VERSION ""

NS_ :

BS_:

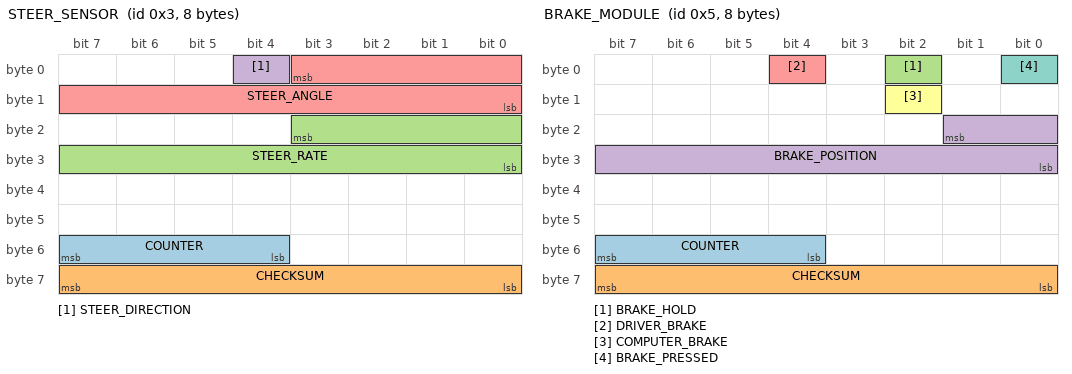
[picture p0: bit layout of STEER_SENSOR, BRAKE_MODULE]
BO_ 3 STEER_SENSOR: 8 XXX
 SG_ COUNTER : 55|4@0+ (1,0) [0|15] "" XXX
 SG_ CHECKSUM : 63|8@0+ (1,0) [0|255] "" XXX
 SG_ STEER_RATE : 19|12@0- (0.5,0) [0|255] "" XXX
 SG_ STEER_DIRECTION : 4|1@0+ (1,2) [0|1] "" XXX
 SG_ STEER_ANGLE : 3|12@0- (-0.5,0) [-500|500] "degrees" XXX

BO_ 5 BRAKE_MODULE: 8 XXX
 SG_ COUNTER : 55|4@0+ (1,0) [0|15] "" XXX
 SG_ CHECKSUM : 63|8@0+ (1,0) [0|255] "" XXX
 SG_ BRAKE_HOLD : 2|1@0+ (1,0) [0|1] "" XXX
 SG_ BRAKE_POSITION : 17|10@0+ (1,0) [0|65535] "" XXX
 SG_ DRIVER_BRAKE : 4|1@0+ (1,0) [0|1] "" XXX
 SG_ COMPUTER_BRAKE : 10|1@0+ (1,0) [0|1] "" XXX
 SG_ BRAKE_PRESSED : 0|1@1+ (1,0) [0|1] "" XXX

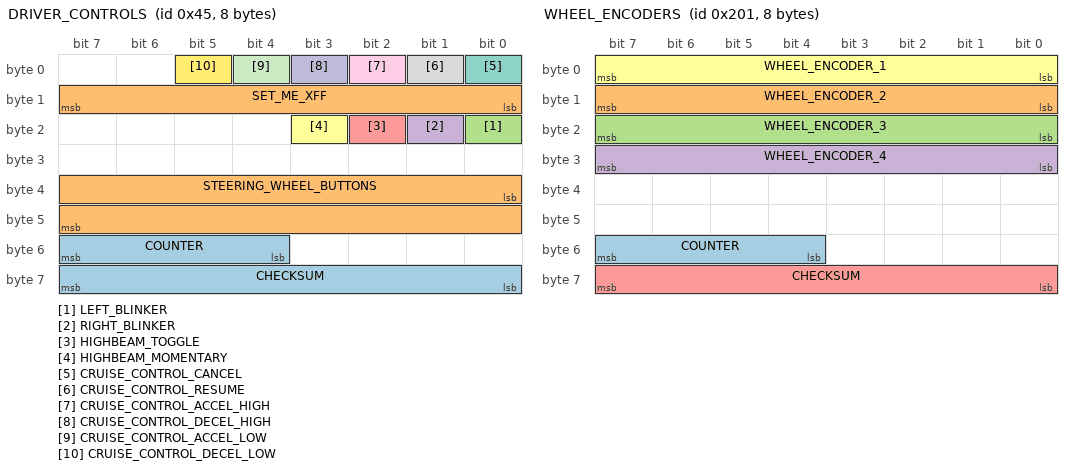
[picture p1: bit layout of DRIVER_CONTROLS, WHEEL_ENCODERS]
BO_ 69 DRIVER_CONTROLS: 8 XXX
 SG_ COUNTER : 55|4@0+ (1,0) [0|15] "" XXX
 SG_ STEERING_WHEEL_BUTTONS : 32|16@1+ (1,0) [0|255] "4 directional, 2 volume control & 2 phone buttons" XXX
 SG_ LEFT_BLINKER : 16|1@0+ (1,0) [0|1] "" XXX
 SG_ RIGHT_BLINKER : 17|1@0+ (1,0) [0|1] "" XXX
 SG_ HIGHBEAM_TOGGLE : 18|1@0+ (1,0) [0|1] "" XXX
 SG_ HIGHBEAM_MOMENTARY : 19|1@0+ (1,0) [0|1] "" XXX
 SG_ CRUISE_CONTROL_CANCEL : 0|1@0+ (1,0) [0|1] "" XXX
 SG_ CRUISE_CONTROL_RESUME : 1|1@0+ (1,0) [0|1] "" XXX
 SG_ CRUISE_CONTROL_ACCEL_HIGH : 2|1@0+ (1,0) [0|1] "" XXX
 SG_ CRUISE_CONTROL_DECEL_HIGH : 3|1@0+ (1,0) [0|1] "" XXX
 SG_ CRUISE_CONTROL_ACCEL_LOW : 4|1@0+ (1,0) [0|1] "" XXX
 SG_ CRUISE_CONTROL_DECEL_LOW : 5|1@0+ (1,0) [0|1] "" XXX
 SG_ CHECKSUM : 63|8@0+ (1,0) [0|255] "" XXX
 SG_ SET_ME_XFF : 15|8@0+ (1,0) [0|255] "" XXX

BO_ 513 WHEEL_ENCODERS: 8 XXX
 SG_ COUNTER : 55|4@0+ (1,0) [0|15] "" XXX
 SG_ WHEEL_ENCODER_2 : 15|8@0+ (1,0) [0|255] "" XXX
 SG_ WHEEL_ENCODER_3 : 23|8@0+ (1,0) [0|255] "" XXX
 SG_ WHEEL_ENCODER_4 : 31|8@0+ (1,0) [0|255] "" XXX
 SG_ CHECKSUM : 56|8@1+ (1,0) [0|255] "" XXX
 SG_ WHEEL_ENCODER_1 : 7|8@0+ (1,0) [0|255] "" XXX

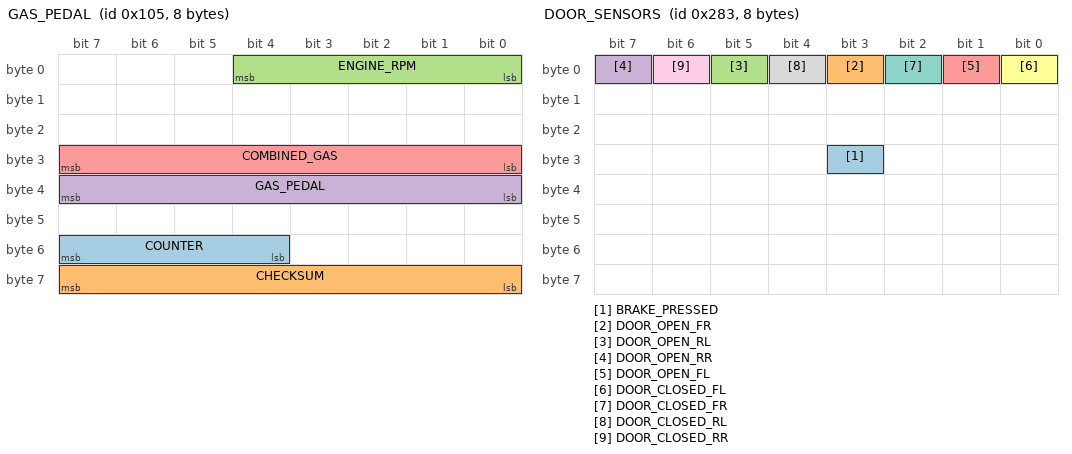
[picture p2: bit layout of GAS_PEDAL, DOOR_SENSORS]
BO_ 261 GAS_PEDAL: 8 XXX
 SG_ COUNTER : 55|4@0+ (1,0) [0|15] "" XXX
 SG_ CHECKSUM : 63|8@0+ (1,0) [0|255] "" XXX
 SG_ ENGINE_RPM : 4|5@0+ (1,0) [0|255] "" XXX
 SG_ GAS_PEDAL : 39|8@0+ (1,0) [0|255] "" XXX
 SG_ COMBINED_GAS : 31|8@0+ (1,0) [0|255] "" XXX

BO_ 643 DOOR_SENSORS: 8 XXX
 SG_ BRAKE_PRESSED : 27|1@0+ (1,0) [0|1] "" XXX
 SG_ DOOR_OPEN_FR : 3|1@1+ (1,0) [0|3] "" XXX
 SG_ DOOR_OPEN_RL : 5|1@0+ (1,0) [0|3] "" XXX
 SG_ DOOR_OPEN_RR : 7|1@0+ (1,0) [0|3] "" XXX
 SG_ DOOR_OPEN_FL : 1|1@0+ (1,0) [0|1] "" XXX
 SG_ DOOR_CLOSED_FL : 0|1@0+ (1,0) [0|1] "" XXX
 SG_ DOOR_CLOSED_FR : 2|1@0+ (1,0) [0|1] "" XXX
 SG_ DOOR_CLOSED_RL : 4|1@0+ (1,0) [0|1] "" XXX
 SG_ DOOR_CLOSED_RR : 6|1@0+ (1,0) [0|1] "" XXX

BO_ 885 SEATBELT_SENSORS: 8 XXX
 SG_ SEATBELT_DRIVER_LATCHED : 16|1@0+ (1,0) [0|1] "" XXX
 SG_ SEATBELT_PASSENGER_LATCHED : 18|1@0+ (1,0) [0|1] "" XXX

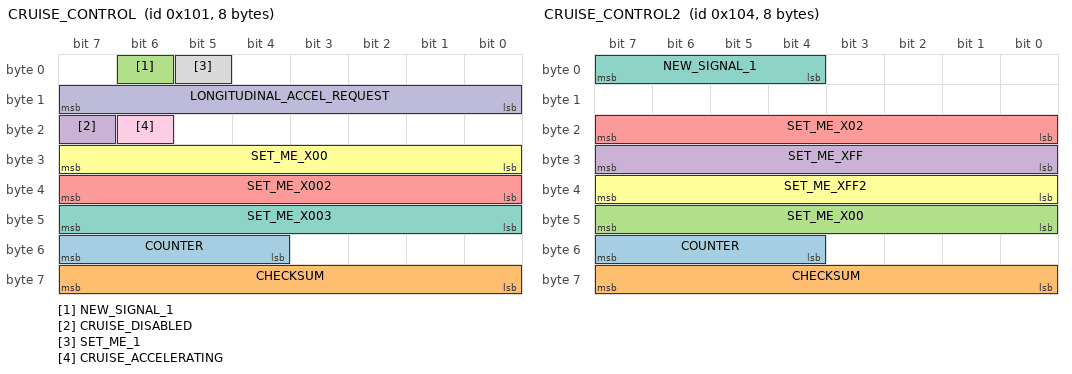
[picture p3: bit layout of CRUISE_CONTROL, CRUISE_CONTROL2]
BO_ 257 CRUISE_CONTROL: 8 XXX
 SG_ COUNTER : 55|4@0+ (1,0) [0|15] "" XXX
 SG_ CHECKSUM : 63|8@0+ (1,0) [0|255] "" XXX
 SG_ NEW_SIGNAL_1 : 6|1@0+ (1,0) [0|255] "" XXX
 SG_ CRUISE_DISABLED : 23|1@0+ (1,0) [0|1] "" XXX
 SG_ SET_ME_X002 : 39|8@0+ (1,0) [0|255] "" XXX
 SG_ SET_ME_X00 : 31|8@0+ (1,0) [0|255] "" XXX
 SG_ SET_ME_X003 : 47|8@0+ (1,0) [0|255] "" XXX
 SG_ SET_ME_1 : 5|1@0+ (1,0) [0|1] "" XXX
 SG_ CRUISE_ACCELERATING : 22|1@0+ (1,0) [0|1] "" XXX
 SG_ LONGITUDINAL_ACCEL_REQUEST : 15|8@0- (1,0) [0|127] "" XXX

BO_ 260 CRUISE_CONTROL2: 8 XXX
 SG_ COUNTER : 55|4@0+ (1,0) [0|15] "" XXX
 SG_ CHECKSUM : 63|8@0+ (1,0) [0|255] "" XXX
 SG_ SET_ME_X00 : 47|8@0+ (1,0) [0|255] "" XXX
 SG_ SET_ME_XFF : 31|8@0+ (1,0) [0|65535] "" XXX
 SG_ SET_ME_X02 : 23|8@0+ (1,0) [0|255] "" XXX
 SG_ SET_ME_XFF2 : 39|8@0+ (1,0) [0|255] "" XXX
 SG_ NEW_SIGNAL_1 : 7|4@0+ (1,0) [0|255] "" XXX

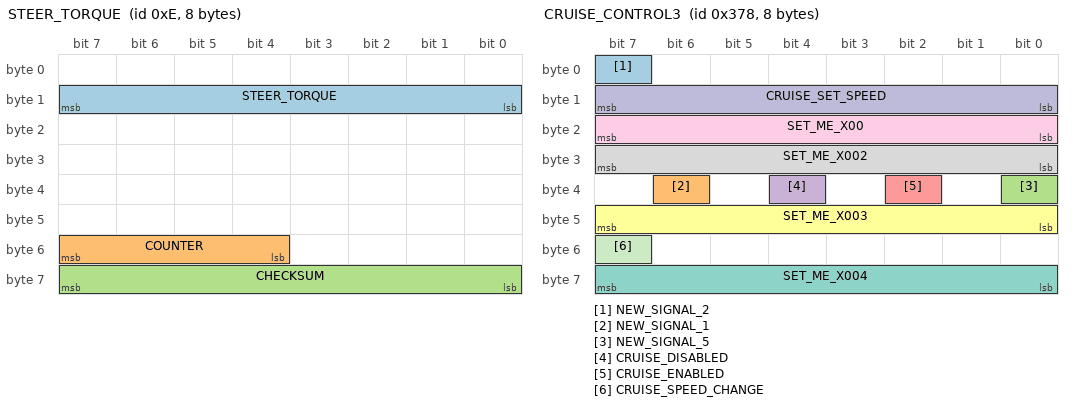
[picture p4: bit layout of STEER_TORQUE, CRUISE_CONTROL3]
BO_ 14 STEER_TORQUE: 8 XXX
 SG_ STEER_TORQUE : 15|8@0+ (1,0) [0|255] "" XXX
 SG_ COUNTER : 55|4@0+ (1,0) [0|15] "" XXX
 SG_ CHECKSUM : 63|8@0+ (1,0) [0|255] "" XXX

BO_ 888 CRUISE_CONTROL3: 8 XXX
 SG_ NEW_SIGNAL_2 : 7|1@0+ (1,0) [0|1] "" XXX
 SG_ NEW_SIGNAL_1 : 38|1@0+ (1,0) [0|1] "" XXX
 SG_ NEW_SIGNAL_5 : 32|1@0+ (1,0) [0|1] "" XXX
 SG_ CRUISE_DISABLED : 36|1@0+ (1,0) [0|1] "" XXX
 SG_ CRUISE_ENABLED : 34|1@0+ (1,0) [0|1] "" XXX
 SG_ SET_ME_X003 : 47|8@0+ (1,0) [0|255] "" XXX
 SG_ SET_ME_X004 : 63|8@0+ (1,0) [0|255] "" XXX
 SG_ SET_ME_X002 : 31|8@0+ (1,0) [0|255] "" XXX
 SG_ SET_ME_X00 : 23|8@0+ (1,0) [0|255] "" XXX
 SG_ CRUISE_SET_SPEED : 15|8@0+ (1,0) [0|63] "mph" XXX
 SG_ CRUISE_SPEED_CHANGE : 55|1@0+ (1,0) [0|1] "" XXX

BO_ 307 POWER_SEATS: 8 XXX
 SG_ DRIVER_FORWARD : 0|1@0+ (1,0) [0|1] "" XXX
 SG_ DRIVER_BACK : 1|1@0+ (1,0) [0|1] "" XXX

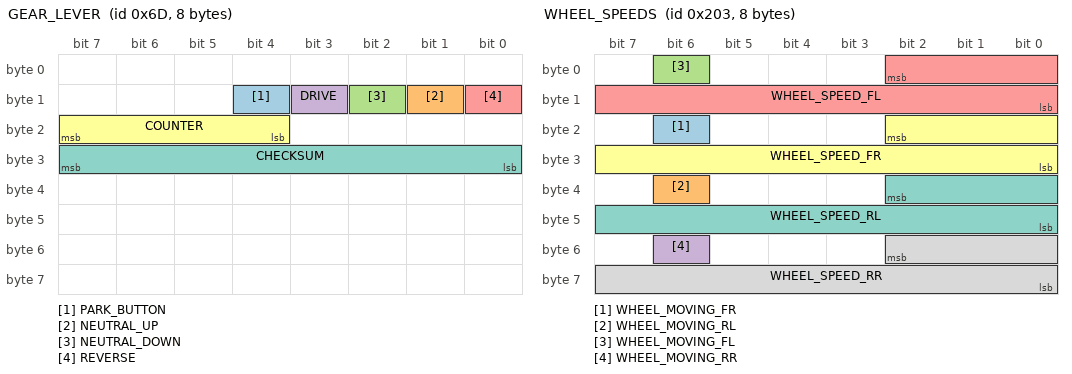
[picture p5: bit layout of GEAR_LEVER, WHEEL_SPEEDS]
BO_ 109 GEAR_LEVER: 8 XXX
 SG_ PARK_BUTTON : 12|1@0+ (1,0) [0|1] "" XXX
 SG_ NEUTRAL_UP : 9|1@0+ (1,0) [0|1] "" XXX
 SG_ NEUTRAL_DOWN : 10|1@0+ (1,0) [0|1] "" XXX
 SG_ DRIVE : 11|1@0+ (1,0) [0|1] "" XXX
 SG_ REVERSE : 8|1@0+ (1,0) [0|1] "" XXX
 SG_ COUNTER : 23|4@0+ (1,0) [0|15] "" XXX
 SG_ CHECKSUM : 31|8@0+ (1,0) [0|255] "" XXX

BO_ 115 GEAR_PACKET: 8 XXX
 SG_ GEAR : 0|4@1+ (1,0) [0|15] "" XXX

BO_ 581 IGNITION: 8 XXX

BO_ 515 WHEEL_SPEEDS: 8 XXX
 SG_ WHEEL_MOVING_FR : 22|1@1+ (1,0) [0|15] "" XXX
 SG_ WHEEL_MOVING_RL : 38|1@0+ (1,0) [0|1] "" XXX
 SG_ WHEEL_MOVING_FL : 6|1@0+ (1,0) [0|1] "" XXX
 SG_ WHEEL_MOVING_RR : 54|1@0+ (1,0) [0|1] "" XXX
 SG_ WHEEL_SPEED_FL : 2|11@0+ (0.0375,0) [0|255] "mph" XXX
 SG_ WHEEL_SPEED_FR : 18|11@0+ (0.0375,0) [0|255] "mph" XXX
 SG_ WHEEL_SPEED_RL : 34|11@0+ (0.0375,0) [0|255] "mph" XXX
 SG_ WHEEL_SPEED_RR : 50|11@0+ (0.0375,0) [0|255] "mph" XXX

BU_: XXX

CM_ "AUTOGENERATED FILE, DO NOT EDIT";

CM_ "Imported file _honda_common.dbc starts here";
CM_ SG_ 304 "Seems to be platform-agnostic";
CM_ SG_ 316 "Should exist on Nidec";
CM_ SG_ 420 BRAKE_HOLD_RELATED "On when Brake Hold engaged";
CM_ SG_ 490 LONG_ACCEL "wheel speed derivative, noisy and zero snapping";
CM_ SG_ 773 PASS_AIRBAG_ON "Might just be indicator light";
CM_ SG_ 773 PASS_AIRBAG_OFF "Might just be indicator light";
CM_ SG_ 780 CRUISE_SPEED "255 = no speed";
CM_ SG_ 780 PCM_SPEED "Used by Nidec";
CM_ SG_ 780 PCM_GAS "Used by Nidec";
CM_ SG_ 804 CRUISE_SPEED_PCM "255 = no speed";

CM_ "Imported file _bosch_2018.dbc starts here";
CM_ SG_ 450 EPB_STATE "3: On, 2: Disengaging, 1: Engaging, 0: Off";
CM_ SG_ 576 LINE_DISTANCE_VISIBLE "Length of line visible, undecoded";
CM_ SG_ 577 LINE_FAR_EDGE_POSITION "Appears to be a measure of line thickness, indicates location of the portion of the line furthest from the car, undecoded";
CM_ SG_ 577 LINE_PARAMETER "Unclear if this is low quality line curvature rate or if this is something else, but it is correlated with line curvature, undecoded";
CM_ SG_ 577 LINE_DASHED "1 = line is dashed";
CM_ SG_ 577 LINE_SOLID "1 = line is solid";

CM_ "Imported file _bosch_adas_2018.dbc starts here";
CM_ SG_ 479 CONTROL_ON "Set to 5 when car is being controlled";
CM_ SG_ 479 AEB_STATUS "set for the duration of AEB event";
CM_ SG_ 479 AEB_BRAKING "set when braking is commanded during AEB event";
CM_ SG_ 479 AEB_PREPARE "set 1s before AEB";
CM_ SG_ 829 BEEP "beeps are pleasant, chimes are for warnngs etc...";

CM_ "Imported file _steering_sensors_a.dbc starts here";
CM_ "honda_crv_ex_2017_can.dbc starts here";

CM_ SG_ 479 RELATED_TO_GAS "bits 7, 3, and 1 set to 1 when gas not applied";
CM_ SG_ 479 GAS_BRAKE "Signed value, negative when braking and positive when applying gas";
